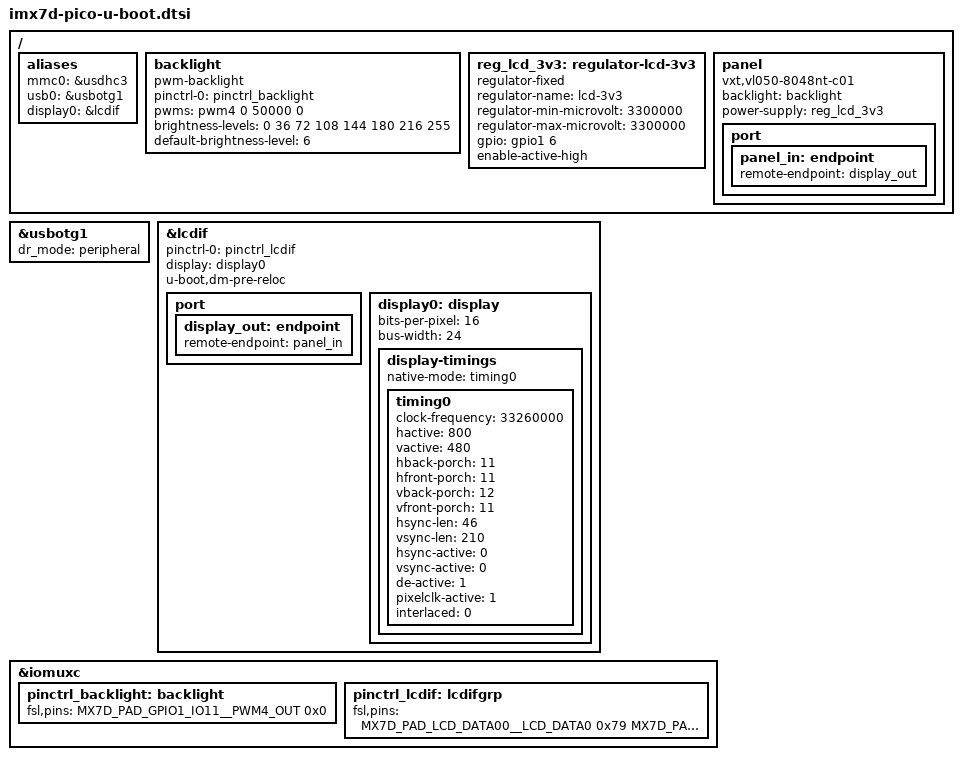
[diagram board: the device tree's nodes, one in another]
/{
    aliases {
        mmc0 = &usdhc3;
        usb0 = &usbotg1;
        display0 = &lcdif;
    };

	backlight: backlight {
		compatible = "pwm-backlight";
		pinctrl-names = "default";
		pinctrl-0 = <&pinctrl_backlight>;
		pwms = <&pwm4 0 50000 0>;
		brightness-levels = <0 36 72 108 144 180 216 255>;
		default-brightness-level = <6>;
		status = "okay";
	};

	reg_lcd_3v3: regulator-lcd-3v3 {
		compatible = "regulator-fixed";
		regulator-name = "lcd-3v3";
		regulator-min-microvolt = <3300000>;
		regulator-max-microvolt = <3300000>;
		gpio = <&gpio1 6 GPIO_ACTIVE_HIGH>;
		enable-active-high;
	};

	panel {
		compatible = "vxt,vl050-8048nt-c01";
		backlight = <&backlight>;
		power-supply = <&reg_lcd_3v3>;

		port {
			panel_in: endpoint {
				remote-endpoint = <&display_out>;
			};
		};
	};
};

&usbotg1 {
	dr_mode = "peripheral";
 };

&lcdif {
	pinctrl-names = "default";
	pinctrl-0 = <&pinctrl_lcdif>;
	status = "okay";
	display = <&display0>;
	u-boot,dm-pre-reloc;

	port {
		display_out: endpoint {
			remote-endpoint = <&panel_in>;
		};
	};

	display0: display {
		bits-per-pixel = <16>;
		bus-width = <24>;

		display-timings {
			native-mode = <&timing0>;
			timing0: timing0 {
				clock-frequency = <33260000>;
				hactive = <800>;
				vactive = <480>;
				hback-porch = <11>;
				hfront-porch = <11>;
				vback-porch = <12>;
				vfront-porch = <11>;
				hsync-len = <46>;
				vsync-len = <210>;
				hsync-active = <0>;
				vsync-active = <0>;
				de-active = <1>;
				pixelclk-active = <1>;
				interlaced =  <0>;
			};
		};
	};
};

&iomuxc {
	pinctrl_backlight: backlight {
		fsl,pins = <
			MX7D_PAD_GPIO1_IO11__PWM4_OUT		0x0
		>;
	};

	pinctrl_lcdif: lcdifgrp {
		fsl,pins = <
			MX7D_PAD_LCD_DATA00__LCD_DATA0		0x79
			MX7D_PAD_LCD_DATA01__LCD_DATA1		0x79
			MX7D_PAD_LCD_DATA02__LCD_DATA2		0x79
			MX7D_PAD_LCD_DATA03__LCD_DATA3		0x79
			MX7D_PAD_LCD_DATA04__LCD_DATA4		0x79
			MX7D_PAD_LCD_DATA05__LCD_DATA5		0x79
			MX7D_PAD_LCD_DATA06__LCD_DATA6		0x79
			MX7D_PAD_LCD_DATA07__LCD_DATA7		0x79
			MX7D_PAD_LCD_DATA08__LCD_DATA8		0x79
			MX7D_PAD_LCD_DATA09__LCD_DATA9		0x79
			MX7D_PAD_LCD_DATA10__LCD_DATA10		0x79
			MX7D_PAD_LCD_DATA11__LCD_DATA11		0x79
			MX7D_PAD_LCD_DATA12__LCD_DATA12		0x79
			MX7D_PAD_LCD_DATA13__LCD_DATA13		0x79
			MX7D_PAD_LCD_DATA14__LCD_DATA14		0x79
			MX7D_PAD_LCD_DATA15__LCD_DATA15		0x79
			MX7D_PAD_LCD_DATA16__LCD_DATA16		0x79
			MX7D_PAD_LCD_DATA17__LCD_DATA17		0x79
			MX7D_PAD_LCD_DATA18__LCD_DATA18		0x79
			MX7D_PAD_LCD_DATA19__LCD_DATA19		0x79
			MX7D_PAD_LCD_DATA20__LCD_DATA20		0x79
			MX7D_PAD_LCD_DATA21__LCD_DATA21		0x79
			MX7D_PAD_LCD_DATA22__LCD_DATA22		0x79
			MX7D_PAD_LCD_DATA23__LCD_DATA23		0x79
			MX7D_PAD_LCD_CLK__LCD_CLK		0x79
			MX7D_PAD_LCD_ENABLE__LCD_ENABLE		0x78
			MX7D_PAD_LCD_VSYNC__LCD_VSYNC		0x78
			MX7D_PAD_LCD_HSYNC__LCD_HSYNC		0x78
			MX7D_PAD_LCD_RESET__GPIO3_IO4		0x14
		>;
	};

};
